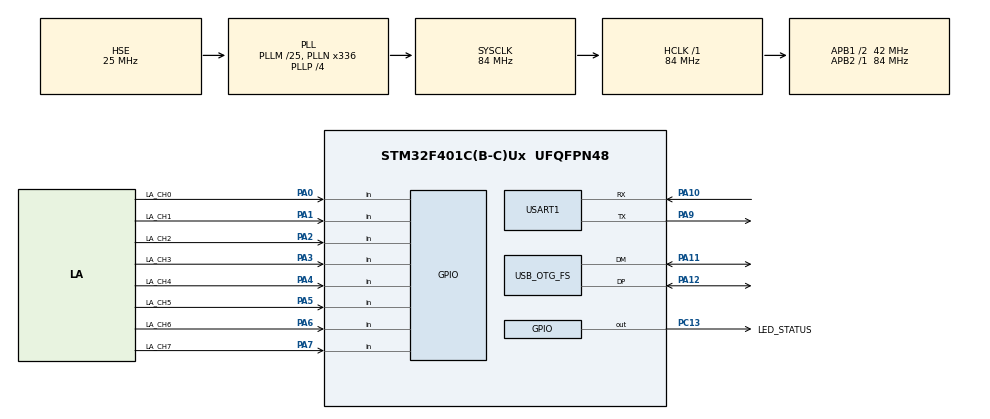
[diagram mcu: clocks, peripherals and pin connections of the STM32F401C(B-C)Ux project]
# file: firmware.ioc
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Dma.Request0=TIM1_UP
Dma.TIM1_UP.0.Direction=DMA_PERIPH_TO_MEMORY
Dma.TIM1_UP.0.FIFOMode=DMA_FIFOMODE_DISABLE
Dma.TIM1_UP.0.Instance=DMA2_Stream5
Dma.TIM1_UP.0.MemDataAlignment=DMA_MDATAALIGN_BYTE
Dma.TIM1_UP.0.MemInc=DMA_MINC_ENABLE
Dma.TIM1_UP.0.Mode=DMA_CIRCULAR
Dma.TIM1_UP.0.PeriphDataAlignment=DMA_PDATAALIGN_BYTE
Dma.TIM1_UP.0.PeriphInc=DMA_PINC_DISABLE
Dma.TIM1_UP.0.Priority=DMA_PRIORITY_VERY_HIGH
Mcu.Family=STM32F4
Mcu.Name=STM32F401C(B-C)Ux
Mcu.Package=UFQFPN48
NVIC.DMA2_Stream5_IRQn=true\:1\:0\:true\:false\:true\:false\:true\:true
NVIC.OTG_FS_IRQn=true\:2\:0\:true\:false\:true\:false\:true\:true
NVIC.PriorityGroup=NVIC_PRIORITYGROUP_4
NVIC.TIM2_IRQn=true\:1\:0\:true\:false\:true\:true\:true\:true
PA0-WKUP.GPIO_Label=LA_CH0
PA0-WKUP.Signal=GPIO_Input
PA1.GPIO_Label=LA_CH1
PA1.Signal=GPIO_Input
PA10.Mode=Asynchronous
PA10.Signal=USART1_RX
PA11.Mode=Device_Only
PA11.Signal=USB_OTG_FS_DM
PA12.Mode=Device_Only
PA12.Signal=USB_OTG_FS_DP
PA13.Mode=Serial_Wire
PA13.Signal=SYS_JTMS-SWDIO
PA14.Mode=Serial_Wire
PA14.Signal=SYS_JTCK-SWCLK
PA2.GPIO_Label=LA_CH2
PA2.Signal=GPIO_Input
PA3.GPIO_Label=LA_CH3
PA3.Signal=GPIO_Input
PA4.GPIO_Label=LA_CH4
PA4.Signal=GPIO_Input
PA5.GPIO_Label=LA_CH5
PA5.Signal=GPIO_Input
PA6.GPIO_Label=LA_CH6
PA6.Signal=GPIO_Input
PA7.GPIO_Label=LA_CH7
PA7.Signal=GPIO_Input
PA9.Mode=Asynchronous
PA9.Signal=USART1_TX
PC13-ANTI_TAMP.GPIO_Label=LED_STATUS
PC13-ANTI_TAMP.Signal=GPIO_Output
PH0\ -\ OSC_IN.Mode=HSE-External-Oscillator
PH0\ -\ OSC_IN.Signal=RCC_OSC_IN
PH1\ -\ OSC_OUT.Mode=HSE-External-Oscillator
PH1\ -\ OSC_OUT.Signal=RCC_OSC_OUT
ProjectManager.HeapSize=0x200
ProjectManager.StackSize=0x400
ProjectManager.TargetToolchain=STM32CubeIDE
RCC.48MHZClocksFreq_Value=48000000
RCC.AHBFreq_Value=84000000
RCC.APB1CLKDivider=RCC_HCLK_DIV2
RCC.APB1Freq_Value=42000000
RCC.APB1TimFreq_Value=84000000
RCC.APB2Freq_Value=84000000
RCC.APB2TimFreq_Value=84000000
RCC.CortexFreq_Value=84000000
RCC.HCLKFreq_Value=84000000
RCC.HSE_VALUE=25000000
RCC.HSI_VALUE=16000000
RCC.LSE_VALUE=32768
RCC.PLLM=25
RCC.PLLN=336
RCC.PLLP=RCC_PLLP_DIV4
RCC.PLLQ=7
RCC.SYSCLKFreq_VALUE=84000000
RCC.SYSCLKSource=RCC_SYSCLKSOURCE_PLLCLK
RCC.VCOOutputFreq_Value=336000000
TIM1.AutoReloadPreload=TIM_AUTORELOAD_PRELOAD_ENABLE
TIM1.Period=83
TIM1.TIM_MasterOutputTrigger=TIM_TRGO_UPDATE
TIM1.TIM_MasterSlaveMode=TIM_MASTERSLAVEMODE_ENABLE
TIM2.Period=26213
USART1.VirtualMode=VM_ASYNC
USB_DEVICE.CLASS_NAME_FS=CDC
USB_DEVICE.VirtualMode=Cdc
USB_DEVICE.VirtualModeFS=Cdc_FS
USB_OTG_FS.VirtualMode=Device_Only
VP_TIM1_VS_ClockSourceINT.Mode=Internal
VP_TIM2_VS_ClockSourceITR.Mode=TriggerSource_ITR0
VP_TIM2_VS_ControllerModeClock.Mode=Clock Mode
VP_TIM2_VS_OPM.Mode=OPM_bit
VP_USB_DEVICE_VS_USB_DEVICE_CDC_FS.Mode=CDC_FS
board=custom

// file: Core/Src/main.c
/* USER CODE BEGIN Header */
/**
  ******************************************************************************
  * @file           : main.c
  * @brief          : Main program body
  ******************************************************************************
  * @attention
  *
  * Copyright (c) 2026 STMicroelectronics.
  * All rights reserved.
  *
  * This software is licensed under terms that can be found in the LICENSE file
  * in the root directory of this software component.
  * If no LICENSE file comes with this software, it is provided AS-IS.
  *
  ******************************************************************************
  */
/* USER CODE END Header */
#include "main.h"
#include "dma.h"
#include "tim.h"
#include "usart.h"
#include "usb_device.h"
#include "gpio.h"

/* USER CODE BEGIN Includes */
#include "la_core.h"
#include "la_protocol.h"
#include "la_testgen.h"
/* USER CODE END Includes */

void SystemClock_Config(void);

int main(void)
{

  /* MCU Configuration--------------------------------------------------------*/

  /* Reset of all peripherals, Initializes the Flash interface and the Systick. */
  HAL_Init();

  /* Configure the system clock */
  SystemClock_Config();

  /* Initialize all configured peripherals */
  MX_GPIO_Init();
  MX_DMA_Init();
  MX_TIM1_Init();
  MX_USB_DEVICE_Init();
  MX_TIM2_Init();
  MX_USART1_UART_Init();
  /* USER CODE BEGIN 2 */
  la_core_init();
  la_testgen_init();
  /* USER CODE END 2 */

  /* Infinite loop */
  while (1)
  {

    /* USER CODE BEGIN 3 */
    la_core_process();
    la_testgen_process();
  }
  /* USER CODE END 3 */
}

void SystemClock_Config(void)
{
  RCC_OscInitTypeDef RCC_OscInitStruct = {0};
  RCC_ClkInitTypeDef RCC_ClkInitStruct = {0};

  /** Configure the main internal regulator output voltage
  */
  __HAL_RCC_PWR_CLK_ENABLE();
  __HAL_PWR_VOLTAGESCALING_CONFIG(PWR_REGULATOR_VOLTAGE_SCALE2);

  /** Initializes the RCC Oscillators according to the specified parameters
  * in the RCC_OscInitTypeDef structure.
  */
  RCC_OscInitStruct.OscillatorType = RCC_OSCILLATORTYPE_HSE;
  RCC_OscInitStruct.HSEState = RCC_HSE_ON;
  RCC_OscInitStruct.PLL.PLLState = RCC_PLL_ON;
  RCC_OscInitStruct.PLL.PLLSource = RCC_PLLSOURCE_HSE;
  RCC_OscInitStruct.PLL.PLLM = 25;
  RCC_OscInitStruct.PLL.PLLN = 336;
  RCC_OscInitStruct.PLL.PLLP = RCC_PLLP_DIV4;
  RCC_OscInitStruct.PLL.PLLQ = 7;
  if (HAL_RCC_OscConfig(&RCC_OscInitStruct) != HAL_OK)
  {
    Error_Handler();
  }

  /** Initializes the CPU, AHB and APB buses clocks
  */
  RCC_ClkInitStruct.ClockType = RCC_CLOCKTYPE_HCLK|RCC_CLOCKTYPE_SYSCLK
                              |RCC_CLOCKTYPE_PCLK1|RCC_CLOCKTYPE_PCLK2;
  RCC_ClkInitStruct.SYSCLKSource = RCC_SYSCLKSOURCE_PLLCLK;
  RCC_ClkInitStruct.AHBCLKDivider = RCC_SYSCLK_DIV1;
  RCC_ClkInitStruct.APB1CLKDivider = RCC_HCLK_DIV2;
  RCC_ClkInitStruct.APB2CLKDivider = RCC_HCLK_DIV1;

  if (HAL_RCC_ClockConfig(&RCC_ClkInitStruct, FLASH_LATENCY_2) != HAL_OK)
  {
    Error_Handler();
  }
}

void Error_Handler(void)
{
  __disable_irq();
  while (1)
  {
  }
}
